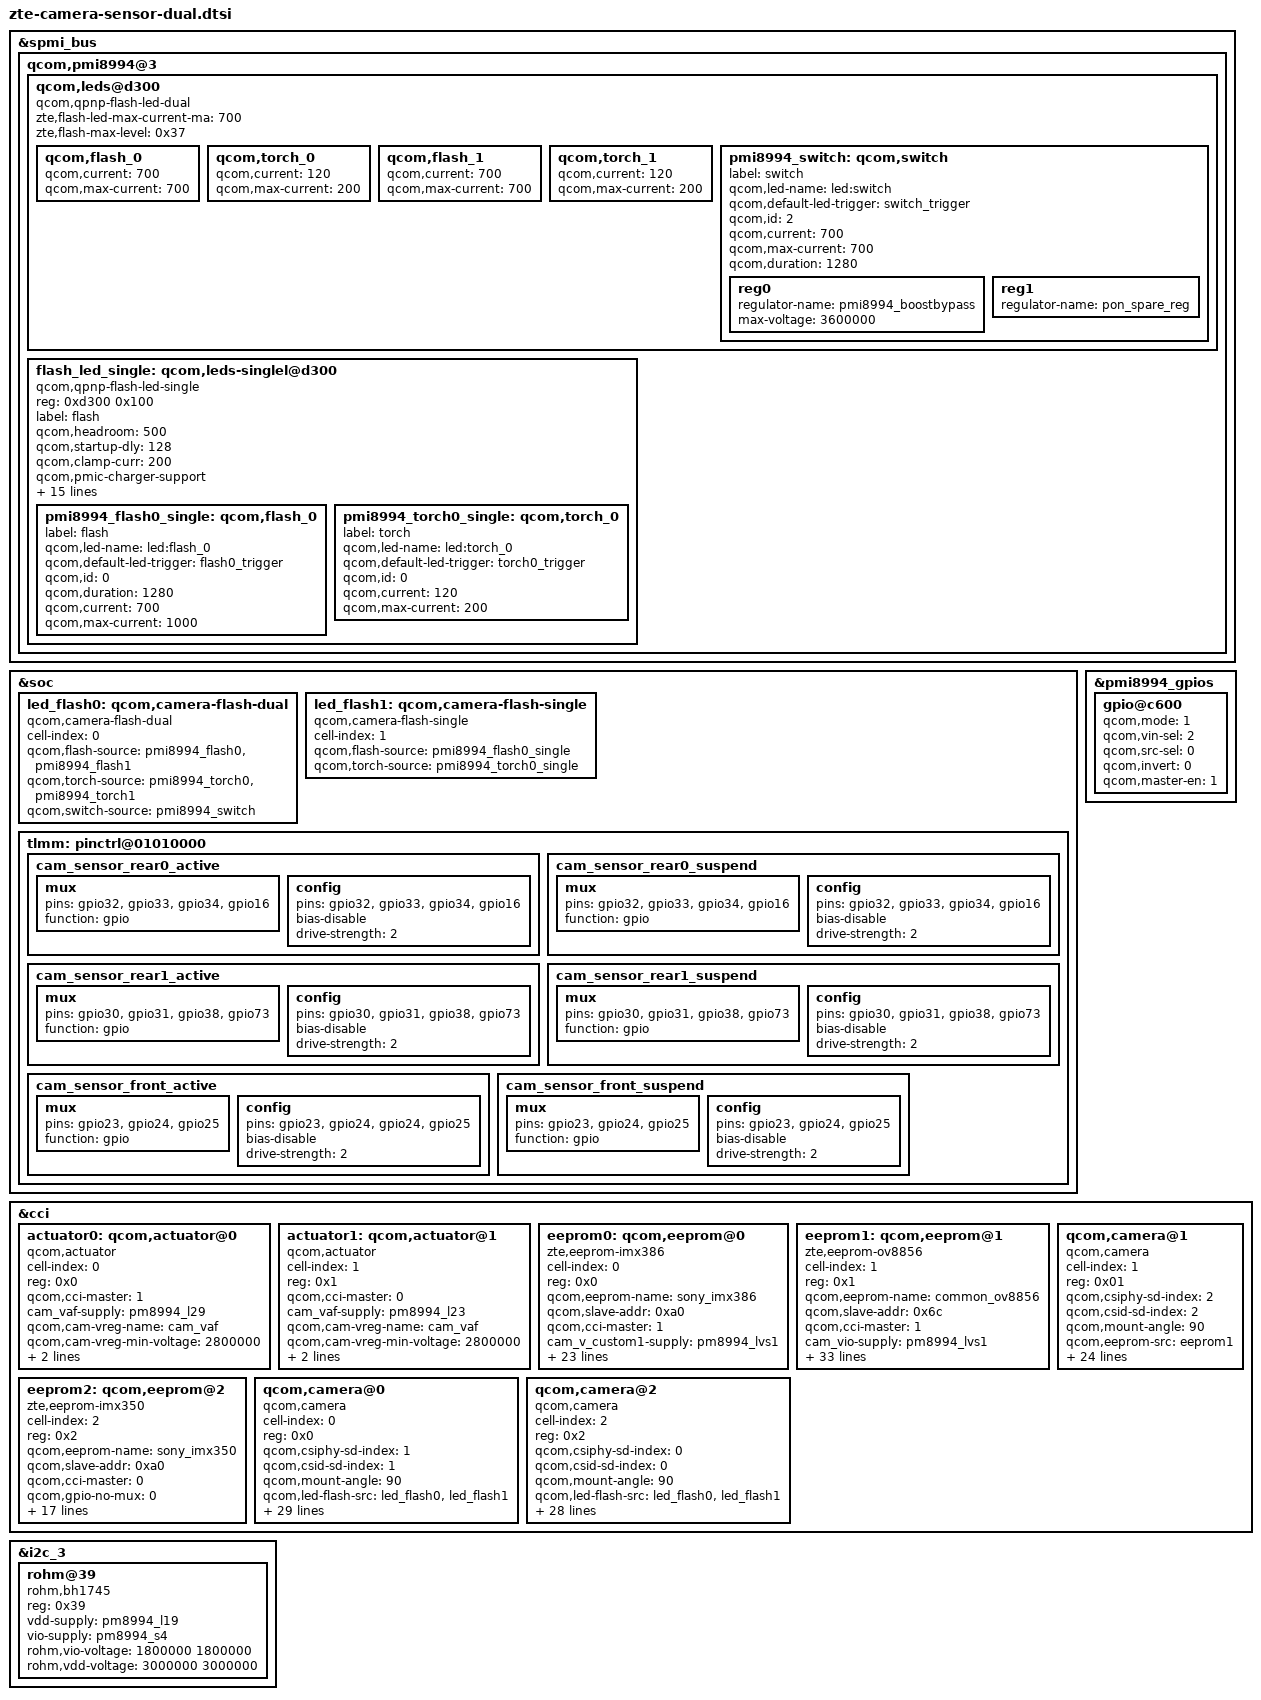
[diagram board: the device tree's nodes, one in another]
/*
 * Copyright (c) 2015 The Linux Foundation. All rights reserved.
 *
 * This program is free software; you can redistribute it and/or modify
 * it under the terms of the GNU General Public License version 2 and
 * only version 2 as published by the Free Software Foundation.
 *
 * This program is distributed in the hope that it will be useful,
 * but WITHOUT ANY WARRANTY; without even the implied warranty of
 * MERCHANTABILITY or FITNESS FOR A PARTICULAR PURPOSE.  See the
 * GNU General Public License for more details.
 */


&spmi_bus {
	qcom,pmi8994@3 {
		qcom,leds@d300 {
		compatible = "qcom,qpnp-flash-led-dual";
		zte,flash-led-max-current-ma = <700>;
		zte,flash-max-level = <0x37>;

		qcom,flash_0{
			qcom,current = <700>;
			qcom,max-current = <700>;
		};

		qcom,torch_0{
			qcom,current = <120>;
			qcom,max-current = <200>;
		};

		qcom,flash_1{
			qcom,current = <700>;
			qcom,max-current = <700>;
		};

		qcom,torch_1{
			qcom,current = <120>;
			qcom,max-current = <200>;
		};

		pmi8994_switch: qcom,switch {
			label = "switch";
			qcom,led-name = "led:switch";
			qcom,default-led-trigger =
					"switch_trigger";
			qcom,id = <2>;
			qcom,current = <700>;
			qcom,max-current = <700>;
			qcom,duration = <1280>;
			reg0 {
				regulator-name =
					"pmi8994_boostbypass";
				max-voltage = <3600000>;
			};
			reg1 {
				regulator-name = "pon_spare_reg";
			};
		};
	};

	flash_led_single: qcom,leds-singlel@d300 {
			compatible = "qcom,qpnp-flash-led-single";
			status = "okay";
			reg = <0xd300 0x100>;
			label = "flash";
			qcom,headroom = <500>;
			qcom,startup-dly = <128>;
			qcom,clamp-curr = <200>;
			qcom,pmic-charger-support;
			qcom,self-check-enabled;
			qcom,thermal-derate-enabled;
			qcom,thermal-derate-threshold = <105>;
			qcom,thermal-derate-rate = "5_PERCENT";
			qcom,current-ramp-enabled;
			qcom,vph-pwr-droop-enabled;
			qcom,vph-pwr-droop-threshold = <3000>;
			qcom,vph-pwr-droop-debounce-time = <10>;
			qcom,headroom-sense-ch0-enabled;
			qcom,headroom-sense-ch1-enabled;
			qcom,power-detect-enabled;
			qcom,pmic-revid = <&pmi8994_revid>;
			qcom,ramp_up_step = "27_US";
			qcom,ramp_dn_step = "27_US";
			qcom,follow-otst2-rb-disabled;

			pmi8994_flash0_single: qcom,flash_0 {
				label = "flash";
				qcom,led-name = "led:flash_0";
				qcom,default-led-trigger =
						"flash0_trigger";
				qcom,id = <0>;
				qcom,duration = <1280>;
				qcom,current = <700>;
				qcom,max-current = <1000>;
			};

			pmi8994_torch0_single: qcom,torch_0 {
				label = "torch";
				qcom,led-name = "led:torch_0";
				qcom,default-led-trigger =
						"torch0_trigger";
				qcom,id = <0>;
				qcom,current = <120>;
				qcom,max-current = <200>;
			};
		};
	};
};
&soc {

	led_flash0: qcom,camera-flash-dual {
		cell-index = <0>;
		compatible = "qcom,camera-flash-dual";
		qcom,flash-source = <&pmi8994_flash0 &pmi8994_flash1>;
		qcom,torch-source = <&pmi8994_torch0 &pmi8994_torch1>;
		qcom,switch-source = <&pmi8994_switch>;
	};

	led_flash1: qcom,camera-flash-single {
		cell-index = <1>;
		compatible = "qcom,camera-flash-single";
		qcom,flash-source = <&pmi8994_flash0_single>;
		qcom,torch-source = <&pmi8994_torch0_single>;
	};

	tlmm: pinctrl@01010000 {
		cam_sensor_rear0_active: cam_sensor_rear0_active {
			mux {
				pins = "gpio32","gpio33","gpio34","gpio16";
				function = "gpio";
			};

			config {
				pins = "gpio32","gpio33","gpio34","gpio16";
				bias-disable; /* No PULL */
				drive-strength = <2>; /* 2 MA */
			};
		};

		cam_sensor_rear0_suspend: cam_sensor_rear0_suspend{
			mux {
				pins = "gpio32","gpio33","gpio34","gpio16";
				function = "gpio";
			};

			config {
				pins = "gpio32","gpio33","gpio34","gpio16";
				bias-disable; /* No PULL */
				drive-strength = <2>; /* 2 MA */
			};
		};

		cam_sensor_rear1_active: cam_sensor_rear1_active {
			mux {
				pins = "gpio30","gpio31","gpio38","gpio73";
				function = "gpio";
			};

			config {
				pins = "gpio30","gpio31","gpio38","gpio73";
				bias-disable; /* No PULL */
				drive-strength = <2>; /* 2 MA */
			};
		};

		cam_sensor_rear1_suspend: cam_sensor_rear1_suspend{
			mux {
				pins = "gpio30","gpio31","gpio38","gpio73";
				function = "gpio";
			};

			config {
				pins = "gpio30","gpio31","gpio38","gpio73";
				bias-disable; /* No PULL */
				drive-strength = <2>; /* 2 MA */
			};
		};

		cam_sensor_front_active: cam_sensor_front_active {
			mux {
				pins = "gpio23","gpio24","gpio25";
				function = "gpio";
			};

			config {
				pins = "gpio23","gpio24","gpio24","gpio25";
				bias-disable; /* No PULL */
				drive-strength = <2>; /* 2 MA */
			};
		};

		cam_sensor_front_suspend: cam_sensor_front_suspend{
			mux {
				pins = "gpio23","gpio24","gpio25";
				function = "gpio";
			};

			config {
				pins = "gpio23","gpio24","gpio25";
				bias-disable; /* No PULL */
				drive-strength = <2>; /* 2 MA */
			};
		};
	};
};

&pmi8994_gpios {
	gpio@c600 {	/* GPIO 7, ois_en  */
		qcom,mode = <1>;
		qcom,vin-sel = <2>;
		qcom,src-sel = <0>;
		qcom,invert = <0>;   /* need invert = 0 */
		qcom,master-en = <1>;
		status = "okay";
	};
};

&cci {
	actuator0: qcom,actuator@0 {
		cell-index = <0>;
		reg = <0x0>;
		compatible = "qcom,actuator";
		qcom,cci-master = <1>;
		cam_vaf-supply = <&pm8994_l29>;
		qcom,cam-vreg-name = "cam_vaf";
		qcom,cam-vreg-min-voltage = <2800000>;
		qcom,cam-vreg-max-voltage = <2800000>;
		qcom,cam-vreg-op-mode = <100000>;
	};

	actuator1: qcom,actuator@1 {
		cell-index = <1>;
		reg = <0x1>;
		compatible = "qcom,actuator";
		qcom,cci-master = <0>;
		cam_vaf-supply = <&pm8994_l23>;
		qcom,cam-vreg-name = "cam_vaf";
		qcom,cam-vreg-min-voltage = <2800000>;
		qcom,cam-vreg-max-voltage = <2800000>;
		qcom,cam-vreg-op-mode = <100000>;
	};

	eeprom0: qcom,eeprom@0{
		compatible = "zte,eeprom-imx386";
		cell-index = <0>;
		reg = <0x0>;
		qcom,eeprom-name = "sony_imx386";
		qcom,slave-addr = <0xa0>;
		qcom,cci-master = <1>;
		cam_v_custom1-supply = <&pm8994_lvs1>;
		qcom,cam-vreg-name = "cam_v_custom1";
		qcom,cam-vreg-min-voltage = <0>;
		qcom,cam-vreg-max-voltage = <0>;
		qcom,cam-vreg-op-mode = <0>;
		qcom,gpio-no-mux = <0>;
		gpios = <&tlmm 34 0>;
		qcom,gpio-vio = <0>;
		qcom,gpio-req-tbl-num = <0>;
		qcom,gpio-req-tbl-flags = <0>;
		qcom,gpio-req-tbl-label = "CAM_IOVDD0";
		pinctrl-names = "cam_default", "cam_suspend";
		pinctrl-0 = <&cam_sensor_rear0_active>;
		pinctrl-1 = <&cam_sensor_rear0_suspend>;
		qcom,cam-power-seq-type =  "sensor_gpio",
									"sensor_vreg",
							"sensor_i2c_mux";
		qcom,cam-power-seq-val = "sensor_gpio_vio",
								 "cam_v_custom1",
								 "none";
		qcom,cam-power-seq-cfg-val = < 1 1 0>;
		qcom,cam-power-seq-delay =   < 0 1 0>;
		zte,num-blocks = <1>;
		zte,mem0    = <8192 0 2 0x0 1 0>;
		clocks = <&clock_mmss clk_mclk0_clk_src>,
			<&clock_mmss clk_camss_mclk0_clk>;
		clock-names = "cam_src_clk", "cam_clk";
		status = "ok";
		qcom,clock-rates = <19200000 0>;
	};

	eeprom1: qcom,eeprom@1{
		compatible = "zte,eeprom-ov8856";
		cell-index = <1>;
		reg = <0x1>;
		qcom,eeprom-name = "common_ov8856";
		qcom,slave-addr = <0x6c>;
		qcom,cci-master = <1>;
		cam_vio-supply = <&pm8994_lvs1>;
		qcom,cam-vreg-name = "cam_vio";
		qcom,cam-vreg-min-voltage = <0>;
		qcom,cam-vreg-max-voltage = <0>;
		qcom,cam-vreg-op-mode = <0>;
		qcom,gpio-no-mux = <0>;
		pinctrl-names = "cam_default", "cam_suspend";
		pinctrl-0 = <&cam_sensor_mclk2_active &cam_sensor_front_active>;
	pinctrl-1 = <&cam_sensor_mclk2_suspend &cam_sensor_front_suspend>;
		gpios = <&tlmm 15 0>,
			<&tlmm 25 0>,
			<&tlmm 24 0>,
		       <&tlmm 23 0>;
		qcom,gpio-vana = <1>;
		qcom,gpio-vdig = <2>;
		qcom,gpio-reset = <3>;
		qcom,gpio-req-tbl-num = <0 1 2 3>;
		qcom,gpio-req-tbl-flags = <1 0 0 0>;
		qcom,gpio-req-tbl-label = "CAMIF_MCLK2",
					  "CAM_AVDD2",
					  "CAM_DVDD2",
					  "CAM_RESET2";
		qcom,cam-power-seq-type = "sensor_gpio",
								     "sensor_vreg",
								     "sensor_gpio",
								     "sensor_gpio",
								     "sensor_clk",
								     "sensor_gpio",
							"sensor_i2c_mux";
		qcom,cam-power-seq-val = "sensor_gpio_reset",
								    "cam_vio",
								    "sensor_gpio_vdig",
								   "sensor_gpio_vana",
								    "sensor_cam_mclk",
								    "sensor_gpio_reset",
								   "none";
		qcom,cam-power-seq-cfg-val = < 0   1 1 1 24000000  1 0>;
		qcom,cam-power-seq-delay =   < 2   0 3 3  2              3 0>;
		zte,num-blocks = <3>;
		zte,mem0    = <17	 0x7010 2 0x0 1 0>;	//id wb
		zte,mem1    = <7	 0x7021 2 0x0 1 0>;  //af
		zte,mem2    = <483	 0x7028 2 0x0 1 0>;  //lens
		clocks = <&clock_mmss clk_mclk2_clk_src>,
			<&clock_mmss clk_camss_mclk2_clk>;
		clock-names = "cam_src_clk", "cam_clk";
		status = "ok";
		qcom,clock-rates = <19200000 0>;
	};

	eeprom2: qcom,eeprom@2{
		compatible = "zte,eeprom-imx350";
		cell-index = <2>;
		reg = <0x2>;
		qcom,eeprom-name = "sony_imx350";
		qcom,slave-addr = <0xa0>;
		qcom,cci-master = <0>;
		qcom,gpio-no-mux = <0>;
		gpios = <&tlmm 73 0>;
		qcom,gpio-vio = <0>;
		qcom,gpio-req-tbl-num = <0>;
		qcom,gpio-req-tbl-flags = <0>;
		qcom,gpio-req-tbl-label = "CAM_IOVDD1";
		pinctrl-names = "cam_default", "cam_suspend";
		pinctrl-0 = <&cam_sensor_rear1_active>;
		pinctrl-1 = <&cam_sensor_rear1_suspend>;
		qcom,cam-power-seq-type = "sensor_gpio",
							"sensor_i2c_mux";
		qcom,cam-power-seq-val = "sensor_gpio_vio",
									"none";
		qcom,cam-power-seq-cfg-val = < 1 0>;
		qcom,cam-power-seq-delay =   < 3 0>;
		zte,num-blocks = <1>;
		zte,mem0    = <8192	 0x0000 2 0x0 1 0>;
		clocks = <&clock_mmss clk_mclk1_clk_src>,
			<&clock_mmss clk_camss_mclk1_clk>;
		clock-names = "cam_src_clk", "cam_clk";
		status = "ok";
		qcom,clock-rates = <19200000 0>;
	};

	qcom,camera@0 {
		cell-index = <0>;
		compatible = "qcom,camera";
		reg = <0x0>;
		qcom,csiphy-sd-index = <1>;
		qcom,csid-sd-index = <1>;
		qcom,mount-angle = <90>;
		qcom,led-flash-src = <&led_flash0 &led_flash1>;
		qcom,eeprom-src = <&eeprom0>;
		qcom,actuator-src = <&actuator0>;
		cam_v_custom1-supply = <&pm8994_lvs1>;
		cam_vaf-supply = <&pm8994_l29>;
		qcom,cam-vreg-name = "cam_v_custom1","cam_vaf";
		qcom,cam-vreg-min-voltage = <0 2800000>;
		qcom,cam-vreg-max-voltage = <0 2800000>;
		qcom,cam-vreg-op-mode = <0 100000>;
		qcom,gpio-no-mux = <0>;
		pinctrl-names = "cam_default", "cam_suspend";
		pinctrl-0 = <&cam_sensor_mclk0_active &cam_sensor_rear0_active>;
	pinctrl-1 = <&cam_sensor_mclk0_suspend &cam_sensor_rear0_suspend>;
		gpios = <&tlmm 13 0>,
			<&tlmm 32 0>,
			<&tlmm 33 0>,
			<&tlmm 34 0>,
			<&tlmm 16 0>;
		qcom,gpio-vana = <1>;
		qcom,gpio-vdig = <2>;
		qcom,gpio-vio = <3>;
		qcom,gpio-reset = <4>;
		qcom,gpio-req-tbl-num = <0 1 2 3 4>;
		qcom,gpio-req-tbl-flags = <1 0 0 0 0>;
		qcom,gpio-req-tbl-label = "CAMIF_MCLK0",
					  "CAM_AVDD0",
					  "CAM_DVDD0",
					  "CAM_IOVDD0",
					  "CAM_RESET0";
		qcom,sensor-position = <0>;
		qcom,sensor-mode = <0>;
		qcom,cci-master = <1>;
		status = "ok";
		clocks = <&clock_mmss clk_mclk0_clk_src>,
				<&clock_mmss clk_camss_mclk0_clk>;
		clock-names = "cam_src_clk", "cam_clk";
		qcom,clock-rates = <24000000 0>;
	};

	qcom,camera@1 {
		cell-index = <1>;
		compatible = "qcom,camera";
		reg = <0x01>;
		qcom,csiphy-sd-index = <2>;
		qcom,csid-sd-index = <2>;
		qcom,mount-angle = <90>;
		qcom,eeprom-src = <&eeprom1>;
		cam_vio-supply = <&pm8994_lvs1>;
		qcom,cam-vreg-name = "cam_vio";
		qcom,cam-vreg-min-voltage = <0>;
		qcom,cam-vreg-max-voltage = <0>;
		qcom,cam-vreg-op-mode = <0>;
		qcom,gpio-no-mux = <0>;
		pinctrl-names = "cam_default", "cam_suspend";
		pinctrl-0 = <&cam_sensor_mclk2_active &cam_sensor_front_active>;
	pinctrl-1 = <&cam_sensor_mclk2_suspend &cam_sensor_front_suspend>;
		gpios = <&tlmm 15 0>,
			<&tlmm 25 0>,
			<&tlmm 24 0>,
		       <&tlmm 23 0>;
		qcom,gpio-vana = <1>;
		qcom,gpio-vdig = <2>;
		qcom,gpio-reset = <3>;
		qcom,gpio-req-tbl-num = <0 1 2 3>;
		qcom,gpio-req-tbl-flags = <1 0 0 0>;
		qcom,gpio-req-tbl-label = "CAMIF_MCLK2",
					  "CAM_AVDD2",
					  "CAM_DVDD2",
					  "CAM_RESET2";
		qcom,sensor-position = <1>;
		qcom,sensor-mode = <0>;
		qcom,cci-master = <1>;
		status = "ok";
		clocks = <&clock_mmss clk_mclk2_clk_src>,
			<&clock_mmss clk_camss_mclk2_clk>;
		clock-names = "cam_src_clk", "cam_clk";
		qcom,clock-rates = <24000000 0>;
	};

	qcom,camera@2 {
		cell-index = <2>;
		compatible = "qcom,camera";
		reg = <0x2>;
		qcom,csiphy-sd-index = <0>;
		qcom,csid-sd-index = <0>;
		qcom,mount-angle = <90>;
		qcom,led-flash-src = <&led_flash0 &led_flash1>;
		qcom,eeprom-src = <&eeprom2>;
		qcom,actuator-src = <&actuator1>;
		cam_vaf-supply = <&pm8994_l23>;
		qcom,cam-vreg-name = "cam_vaf";
		qcom,cam-vreg-min-voltage = <2800000>;
		qcom,cam-vreg-max-voltage = <2800000>;
		qcom,cam-vreg-op-mode = <100000>;
		qcom,gpio-no-mux = <0>;
		pinctrl-names = "cam_default", "cam_suspend";
		pinctrl-0 = <&cam_sensor_mclk1_active &cam_sensor_rear1_active>;
	pinctrl-1 = <&cam_sensor_mclk1_suspend &cam_sensor_rear1_suspend>;
		gpios = <&tlmm 14 0>,
			<&tlmm 31 0>,
			<&tlmm 38 0>,
			<&tlmm 73 0>,
			<&tlmm 30 0>;
		qcom,gpio-vana = <1>;
		qcom,gpio-vdig = <2>;
		qcom,gpio-vio = <3>;
		qcom,gpio-reset = <4>;
		qcom,gpio-req-tbl-num = <0 1 2 3 4>;
		qcom,gpio-req-tbl-flags = <1 0 0 0 0>;
		qcom,gpio-req-tbl-label = "CAMIF_MCLK1",
					  "CAM_AVDD1",
					  "CAM_DVDD1",
					  "CAM_IOVDD1",
					  "CAM_RESET1";
		qcom,sensor-position = <0>;
		qcom,sensor-mode = <0>;
		qcom,cci-master = <0>;
		status = "ok";
		clocks = <&clock_mmss clk_mclk1_clk_src>,
				<&clock_mmss clk_camss_mclk1_clk>;
		clock-names = "cam_src_clk", "cam_clk";
		qcom,clock-rates = <24000000 0>;
	};
};
&i2c_3 {
	status = "okay";
	rohm@39{
		compatible = "rohm,bh1745";
		reg = <0x39>;
		vdd-supply = <&pm8994_l19>;
		vio-supply = <&pm8994_s4>;
		rohm,vio-voltage = <1800000 1800000>;
		rohm,vdd-voltage = <3000000 3000000>;
	};
};

